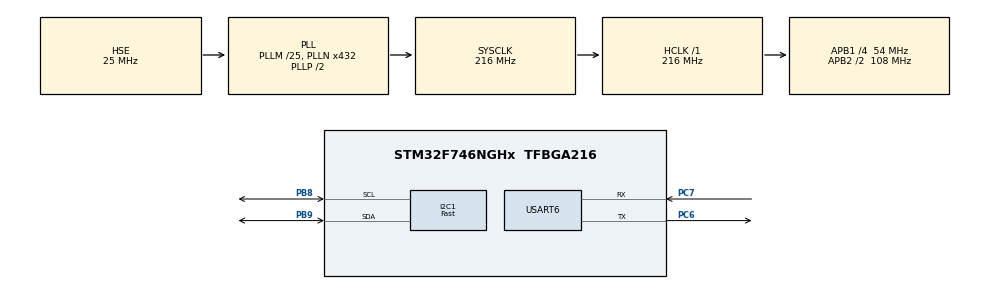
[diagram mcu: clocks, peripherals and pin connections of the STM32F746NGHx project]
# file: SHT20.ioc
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I2C1.I2C_Speed_Mode=I2C_Fast
I2C1.Timing=0x6000030D
Mcu.Family=STM32F7
Mcu.Name=STM32F746NGHx
Mcu.Package=TFBGA216
NVIC.PriorityGroup=NVIC_PRIORITYGROUP_4
PB8.Mode=I2C
PB8.Signal=I2C1_SCL
PB9.Mode=I2C
PB9.Signal=I2C1_SDA
PC6.Mode=Asynchronous
PC6.Signal=USART6_TX
PC7.Mode=Asynchronous
PC7.Signal=USART6_RX
PH0/OSC_IN.Mode=HSE-External-Oscillator
PH0/OSC_IN.Signal=RCC_OSC_IN
PH1/OSC_OUT.Mode=HSE-External-Oscillator
PH1/OSC_OUT.Signal=RCC_OSC_OUT
ProjectManager.HeapSize=0x200
ProjectManager.StackSize=0x400
ProjectManager.TargetToolchain=STM32CubeIDE
RCC.AHBFreq_Value=216000000
RCC.APB1CLKDivider=RCC_HCLK_DIV4
RCC.APB1Freq_Value=54000000
RCC.APB1TimFreq_Value=108000000
RCC.APB2CLKDivider=RCC_HCLK_DIV2
RCC.APB2Freq_Value=108000000
RCC.APB2TimFreq_Value=216000000
RCC.CortexFreq_Value=216000000
RCC.HCLKFreq_Value=216000000
RCC.HSE_VALUE=25000000
RCC.HSI_VALUE=16000000
RCC.LSE_VALUE=32768
RCC.PLLM=25
RCC.PLLN=432
RCC.PLLSourceVirtual=RCC_PLLSOURCE_HSE
RCC.SYSCLKFreq_VALUE=216000000
RCC.SYSCLKSource=RCC_SYSCLKSOURCE_PLLCLK
RCC.USBFreq_Value=216000000
RCC.VCOOutputFreq_Value=432000000
USART6.VirtualMode-Asynchronous=VM_ASYNC
board=custom

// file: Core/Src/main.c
/* USER CODE BEGIN Header */
/**
  ******************************************************************************
  * @file           : main.c
  * @brief          : Main program body
  ******************************************************************************
  * @attention
  *
  * <h2><center>&copy; Copyright (c) 2020 STMicroelectronics.
  * All rights reserved.</center></h2>
  *
  * This software component is licensed by ST under BSD 3-Clause license,
  * the "License"; You may not use this file except in compliance with the
  * License. You may obtain a copy of the License at:
  *                        opensource.org/licenses/BSD-3-Clause
  *
  ******************************************************************************
  */
/* USER CODE END Header */

#include "main.h"
#include "i2c.h"
#include "usart.h"
#include "gpio.h"

/* USER CODE BEGIN Includes */
#include "debug.h"
#include "sht20.h"
/* USER CODE END Includes */

void SystemClock_Config(void);

int main(void)
{

  /* MCU Configuration--------------------------------------------------------*/

  /* Reset of all peripherals, Initializes the Flash interface and the Systick. */
  HAL_Init();

  /* Configure the system clock */
  SystemClock_Config();

  /* Initialize all configured peripherals */
  MX_GPIO_Init();
  MX_I2C1_Init();
  MX_USART6_UART_Init();
  /* USER CODE BEGIN 2 */
  SHT20_HandelTypedef SHT;
  SHT.hardware.pI2C=&hi2c1;
  SHT.configuration.OTPReload=DISABLE;
  SHT.configuration.onChipHeater=ENABLE;
  SHT.configuration.meaturementResulation=SHT20_MEATUREMENT_RESULATION_08_12;
  sht20_init(&SHT);
  uint8_t data;int ret=0;
  uint8_t recvTemp[3];
  /* USER CODE END 2 */

  /* Infinite loop */
  while (1)
  {

    /* USER CODE BEGIN 3 */
	  ret= sht20_getTemperature(&SHT,&recvTemp,HOLD_MASTER);
	  printf("return of sht20_getTemperature_holdMaster is %d\r\n",ret);
	 // HAL_Delay(500);
	  //ret= sht20_getTemperature(&SHT,&recvTemp,NO_HOLD_MASTER);
	  //printf("return of sht20_getTemperature_noHoldMaster is %d\r\n",ret);
	 // HAL_Delay(500);
	  ret= sht20_getHumidity(&SHT,&recvTemp,HOLD_MASTER);
	  //printf("return of sht20_getTemperature_holdMaster is %d\r\n",ret);
	  //HAL_Delay(500);
//	  ret= sht20_getHumidity(&SHT,&recvTemp,NO_HOLD_MASTER);
	  //printf("return of sht20_getTemperature_noHoldMaster is %d\r\n",ret);
	  HAL_Delay(500);
  }
  /* USER CODE END 3 */
}

void SystemClock_Config(void)
{
  RCC_OscInitTypeDef RCC_OscInitStruct = {0};
  RCC_ClkInitTypeDef RCC_ClkInitStruct = {0};
  RCC_PeriphCLKInitTypeDef PeriphClkInitStruct = {0};

  /** Configure the main internal regulator output voltage
  */
  __HAL_RCC_PWR_CLK_ENABLE();
  __HAL_PWR_VOLTAGESCALING_CONFIG(PWR_REGULATOR_VOLTAGE_SCALE1);
  /** Initializes the CPU, AHB and APB busses clocks
  */
  RCC_OscInitStruct.OscillatorType = RCC_OSCILLATORTYPE_HSE;
  RCC_OscInitStruct.HSEState = RCC_HSE_ON;
  RCC_OscInitStruct.PLL.PLLState = RCC_PLL_ON;
  RCC_OscInitStruct.PLL.PLLSource = RCC_PLLSOURCE_HSE;
  RCC_OscInitStruct.PLL.PLLM = 25;
  RCC_OscInitStruct.PLL.PLLN = 432;
  RCC_OscInitStruct.PLL.PLLP = RCC_PLLP_DIV2;
  RCC_OscInitStruct.PLL.PLLQ = 2;
  if (HAL_RCC_OscConfig(&RCC_OscInitStruct) != HAL_OK)
  {
    Error_Handler();
  }
  /** Activate the Over-Drive mode
  */
  if (HAL_PWREx_EnableOverDrive() != HAL_OK)
  {
    Error_Handler();
  }
  /** Initializes the CPU, AHB and APB busses clocks
  */
  RCC_ClkInitStruct.ClockType = RCC_CLOCKTYPE_HCLK|RCC_CLOCKTYPE_SYSCLK
                              |RCC_CLOCKTYPE_PCLK1|RCC_CLOCKTYPE_PCLK2;
  RCC_ClkInitStruct.SYSCLKSource = RCC_SYSCLKSOURCE_PLLCLK;
  RCC_ClkInitStruct.AHBCLKDivider = RCC_SYSCLK_DIV1;
  RCC_ClkInitStruct.APB1CLKDivider = RCC_HCLK_DIV4;
  RCC_ClkInitStruct.APB2CLKDivider = RCC_HCLK_DIV2;

  if (HAL_RCC_ClockConfig(&RCC_ClkInitStruct, FLASH_LATENCY_7) != HAL_OK)
  {
    Error_Handler();
  }
  PeriphClkInitStruct.PeriphClockSelection = RCC_PERIPHCLK_USART6|RCC_PERIPHCLK_I2C1;
  PeriphClkInitStruct.Usart6ClockSelection = RCC_USART6CLKSOURCE_PCLK2;
  PeriphClkInitStruct.I2c1ClockSelection = RCC_I2C1CLKSOURCE_PCLK1;
  if (HAL_RCCEx_PeriphCLKConfig(&PeriphClkInitStruct) != HAL_OK)
  {
    Error_Handler();
  }
}

void Error_Handler(void)
{
}

/************************ (C) COPYRIGHT STMicroelectronics *****END OF FILE****/
